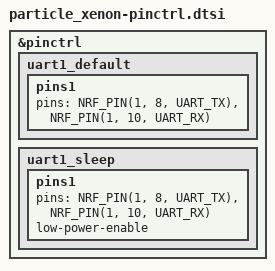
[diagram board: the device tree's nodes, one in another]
/*
 * Copyright (c) 2021 Nordic Semiconductor ASA
 * SPDX-License-Identifier: Apache-2.0
 */

&pinctrl {
	uart1_default: uart1_default {
		pins1 {
			pins = <NRF_PIN(1, 8, UART_TX)>,
			       <NRF_PIN(1, 10, UART_RX)>;
		};
	};

	uart1_sleep: uart1_sleep {
		pins1 {
			pins = <NRF_PIN(1, 8, UART_TX)>,
			       <NRF_PIN(1, 10, UART_RX)>;
			low-power-enable;
		};
	};

};
